# STM32L562xx register map
File version: 1.0
Registers are 32-bit, read-write, reset 0x0 unless marked. A register's access mark holds for its fields unless they carry their own. Offsets are from the block's base; [hi:lo] are bit positions.

## LPTIM1 — LPTIMER
Base 0x40007C00
Same registers: LPTIM2 0x40009400, LPTIM3 0x40009800, LPTIM1_S 0x50007C00, LPTIM2_S 0x50009400, LPTIM3_S 0x50009800
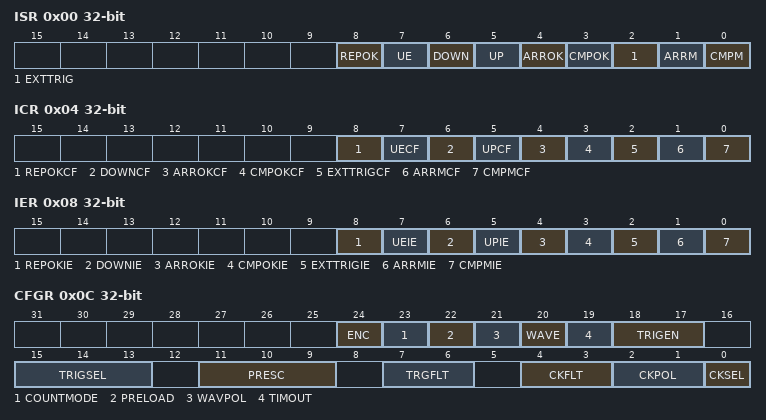
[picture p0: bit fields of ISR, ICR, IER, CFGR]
0x00 ISR — LPTIM Interrupt and Status register
  [8] REPOK — Repetition register update OK
  [7] UE — Update event occurrence
  [6] DOWN — Counter direction change up to down
  [5] UP — Counter direction change down to up
  [4] ARROK — Autoreload register update OK
  [3] CMPOK — Compare register update OK
  [2] EXTTRIG — External trigger edge event
  [1] ARRM — Autoreload match
  [0] CMPM — Compare match
0x04 ICR — LPTIM Interrupt Clear register
  [8] REPOKCF — Repetition register update OK Clear Flag
  [7] UECF — Update event Clear Flag
  [6] DOWNCF — Counter direction change up to down Clear Flag
  [5] UPCF — Counter direction change down to up Clear Flag
  [4] ARROKCF — Autoreload register update OK Clear Flag
  [3] CMPOKCF — Compare register update OK Clear Flag
  [2] EXTTRIGCF — External trigger edge event Clear Flag
  [1] ARRMCF — Autoreload match Clear Flag
  [0] CMPMCF — Compare match Clear Flag
0x08 IER — LPTIM Interrupt Enable register
  [8] REPOKIE — Repetition register update OK Interrupt Enable
  [7] UEIE — Update event Interrupt Enable
  [6] DOWNIE — Counter direction change up to down Interrupt Enable
  [5] UPIE — Counter direction change down to up Interrupt Enable
  [4] ARROKIE — Autoreload register update OK Interrupt Enable
  [3] CMPOKIE — Compare register update OK Interrupt Enable
  [2] EXTTRIGIE — External trigger edge event Interrupt Enable
  [1] ARRMIE — Autoreload match Interrupt Enable
  [0] CMPMIE — Compare match Interrupt Enable
0x0C CFGR — LPTIM Configuration register
  [24] ENC — Encoder mode enable
  [23] COUNTMODE — Counter mode enable
    0=INTERNAL (The counter is incremented following each internal clock pulse); 1=EXTERNAL (The counter is incremented following each valid clock pulse on the LPTIM external Input1)
  [22] PRELOAD — Reg update mode
    0=IMMEDIATE (Preload is disabled: registers are updated after each APB bus write access); 1=ENDOFPERIOD (preload is enabled: registers are updated at the end of the current LPTIM period)
  [21] WAVPOL — Waveform shape polarity
    0=REGULAR (The LPTIM output reflects the compare results between LPTIMx_ARR and LPTIMx_CMP registers); 1=INVERSE (The LPTIM output reflects the inverse of the compare results between LPTIMx_ARR and LPTIMx_CMP registers)
  [20] WAVE — Waveform shape
    0=PWM (LPTIM generates either a PWM waveform or a One pulse waveform depending on chosen operating mode CONTINUOUS or SINGLE); 1=SETONCE (LPTIM generates a Set Once waveform)
  [19] TIMOUT — Timeout enable
  [18:17] TRIGEN — TRIGEN[1:0] bits (Trigger enable and polarity)
    1=RISING (LPTIM counter starts when a rising edge is detected); 2=FALLING (LPTIM counter starts when a falling edge is detected); 3=RISING_FALLING (LPTIM counter starts when a rising or a falling edge is detected)
  [15:13] TRIGSEL — TRIGSEL[2:0]] bits (Trigger selector)
    0=GPIO (External input trigger is connected to TIMx_ETR input); 1=RTCALARMA (External input trigger is connected to RTC Alarm A); 2=RTCALARMB (External input trigger is connected to RTC Alarm B); 3=RTCTAMP1 (External input trigger is connected to RTC Tamper 1); 4=RTCTAMP2 (External input trigger is connected to RTC Tamper 2); 5=RTCTAMP3 (External input trigger is connected to RTC Tamper 3); 6=COMP1 (External input trigger is connected to COMP1 output); 7=COMP2 (External input trigger is connected to COMP2 output)
  [11:9] PRESC — PRESC[2:0] bits (Clock prescaler)
    0=DIV1 (Prescaler division factor is set to 1); 1=DIV2 (Prescaler division factor is set to 2); 2=DIV4 (Prescaler division factor is set to 4); 3=DIV8 (Prescaler division factor is set to 8); 4=DIV16 (Prescaler division factor is set to 16); 5=DIV32 (Prescaler division factor is set to 32); 6=DIV64 (Prescaler division factor is set to 64); 7=DIV128 (Prescaler division factor is set to 128)
  [7:6] TRGFLT — TRGFLT[1:0] bits (Configurable digital filter for trigger)
    0=NONE (Any trigger active level change is considered as a valid trigger); 1=FILTER_2 (Trigger active level change must be stable for at least 2 clock periods before it is considered as valid trigger); 2=FILTER_4 (Trigger active level change must be stable for at least 4 clock periods before it is considered as valid trigger); 3=FILTER_8 (Trigger active level change must be stable for at least 8 clock periods before it is considered as valid trigger)
  [4:3] CKFLT — CKFLT[1:0] bits (Configurable digital filter for external clock)
    0=NONE (Any external clock signal level change is considered as a valid transition); 1=FILTER_2 (External clock signal level change must be stable for at least 2 clock periods before it is considered as valid transition); 2=FILTER_4 (External clock signal level change must be stable for at least 4 clock periods before it is considered as valid transition); 3=FILTER_8 (External clock signal level change must be stable for at least 8 clock periods before it is considered as valid transition)
  [2:1] CKPOL — CKPOL[1:0] bits (Clock polarity)
    0=RISING (The rising edge is the active edge used for counting); 1=FALLING (The falling edge is the active edge used for counting); 2=RISING_FALLING (Both edges are active edges)
  [0] CKSEL — Clock selector
    0=INTERNAL (LPTIM is clocked by internal clock source (APB clock or any of the embedded oscillators)); 1=EXTERNAL (LPTIM is clocked by an external clock source through the LPTIM external Input1)
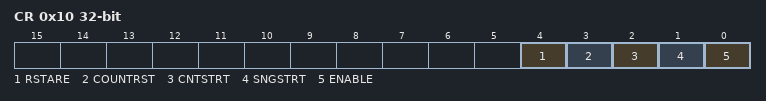
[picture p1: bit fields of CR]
0x10 CR — LPTIM Control register
  [4] RSTARE — Reset after read enable
  [3] COUNTRST — Counter reset
  [2] CNTSTRT — Timer start in continuous mode
  [1] SNGSTRT — Timer start in single mode
  [0] ENABLE — LPTIMer enable
0x14 CMP — LPTIM Compare register
  [15:0] CMP — Compare register
0x18 ARR — LPTIM Autoreload register
  [15:0] ARR — Auto reload register
0x1C CNT — LPTIM Counter register
  [15:0] CNT — Counter register
0x20 OR — LPTIM Option register
  [1:0] OR — OR[1:0] bits (Remap selection)
    0=GPIO (For LPTIM1 and LPTIM2); 1=COMP1 (For LPTIM1 and LPTIM2); 2=COMP2 (For LPTIM2); 3=COMP1_COMP2 (For LPTIM2)
0x28 RCR — LPTIM Repetition counter register
  [7:0] REP — Repetition Counter Value
